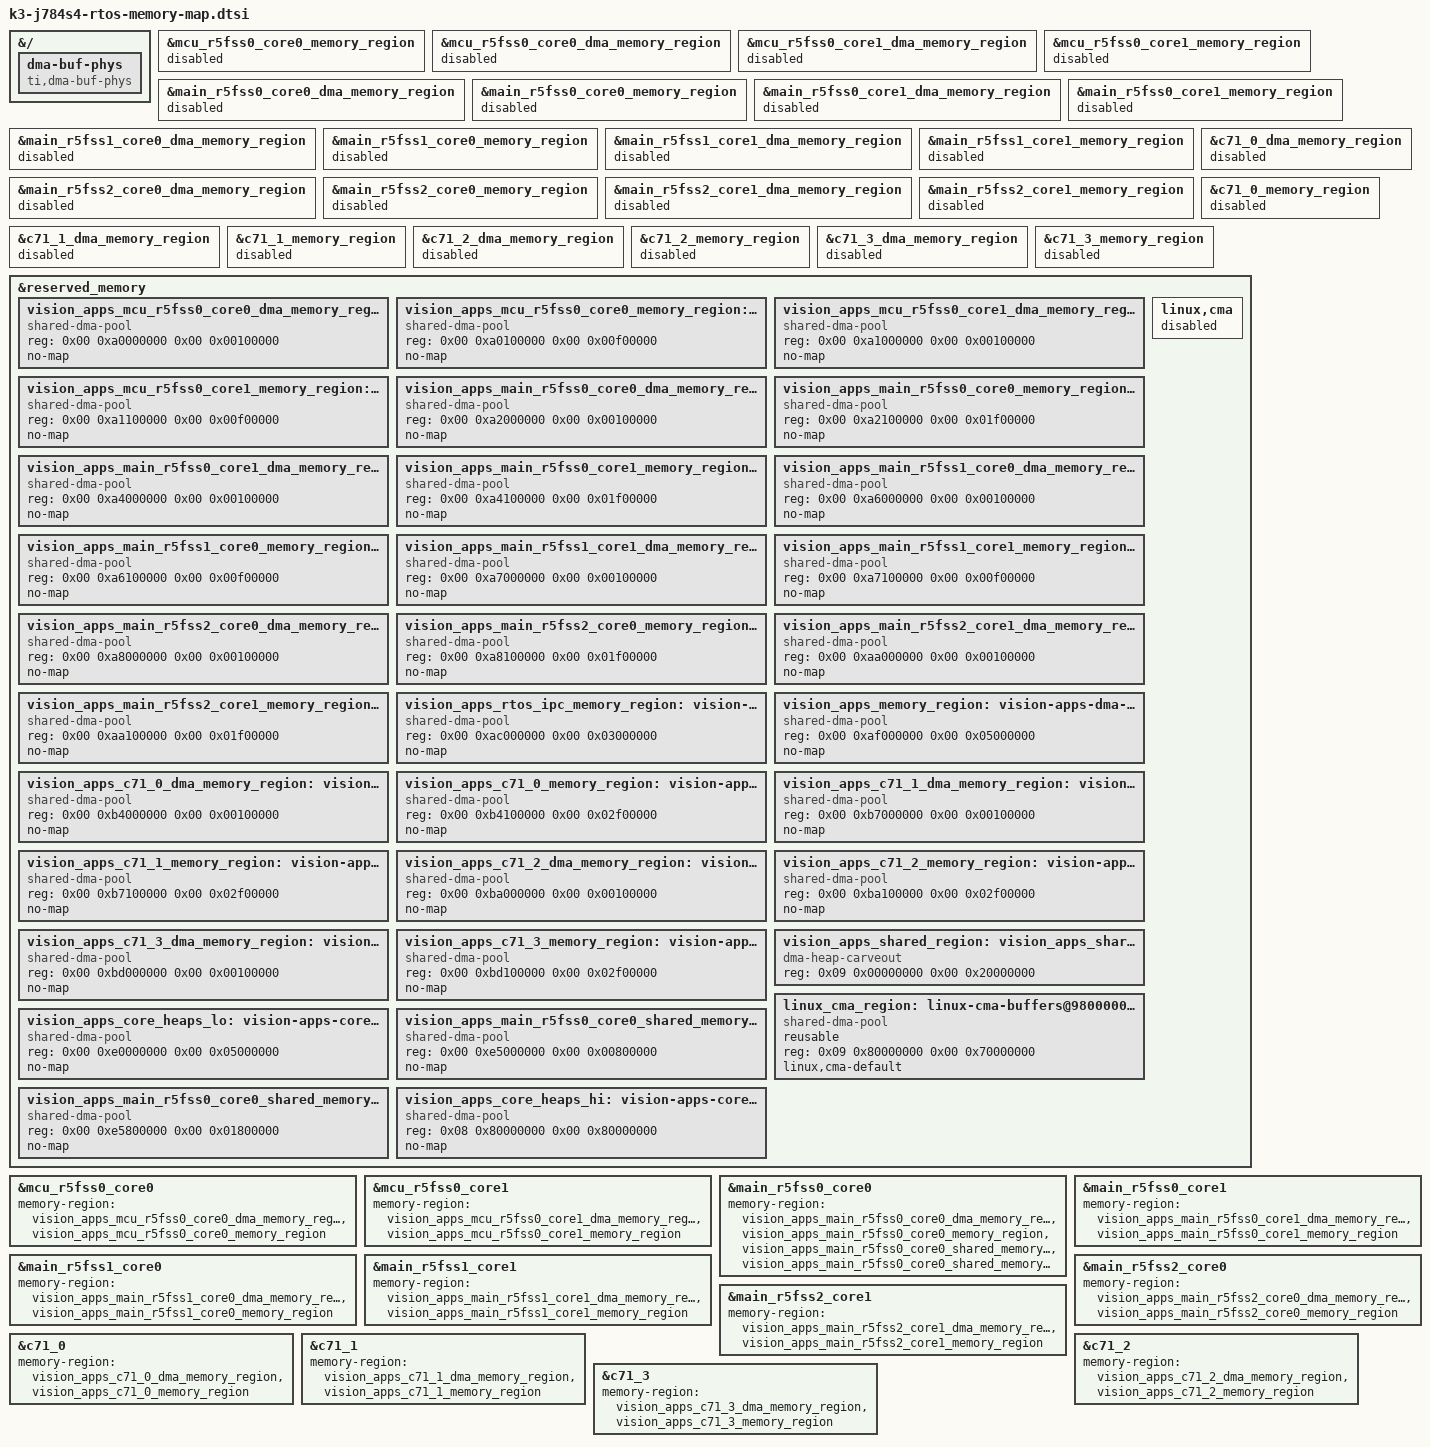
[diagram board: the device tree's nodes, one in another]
// SPDX-License-Identifier: GPL-2.0
/*
 * Vision-apps: device-tree overlay
 *
 * Copyright (C) 2019 - 2022 Texas Instruments Incorporated - http://www.ti.com/
 */

#include <dt-bindings/soc/ti,sci_pm_domain.h>

&{/} {
	dma-buf-phys {
		compatible = "ti,dma-buf-phys";
	};
};

&mcu_r5fss0_core0_memory_region {
	status = "disabled";
};

&mcu_r5fss0_core0_dma_memory_region {
	status = "disabled";
};

&mcu_r5fss0_core1_dma_memory_region {
	status = "disabled";
};

&mcu_r5fss0_core1_memory_region {
	status = "disabled";
};

&main_r5fss0_core0_dma_memory_region {
	status = "disabled";
};

&main_r5fss0_core0_memory_region {
	status = "disabled";
};

&main_r5fss0_core1_dma_memory_region {
	status = "disabled";
};

&main_r5fss0_core1_memory_region {
	status = "disabled";
};

&main_r5fss1_core0_dma_memory_region {
	status = "disabled";
};

&main_r5fss1_core0_memory_region {
	status = "disabled";
};

&main_r5fss1_core1_dma_memory_region {
	status = "disabled";
};

&main_r5fss1_core1_memory_region {
	status = "disabled";
};

&main_r5fss2_core0_dma_memory_region {
	status = "disabled";
};

&main_r5fss2_core0_memory_region {
	status = "disabled";
};

&main_r5fss2_core1_dma_memory_region {
	status = "disabled";
};

&main_r5fss2_core1_memory_region {
	status = "disabled";
};

&c71_0_dma_memory_region {
	status = "disabled";
};

&c71_0_memory_region {
	status = "disabled";
};

&c71_1_dma_memory_region {
	status = "disabled";
};

&c71_1_memory_region {
	status = "disabled";
};

&c71_2_dma_memory_region {
	status = "disabled";
};

&c71_2_memory_region {
	status = "disabled";
};

&c71_3_dma_memory_region {
	status = "disabled";
};

&c71_3_memory_region {
	status = "disabled";
};

&reserved_memory {
	#address-cells = <2>;
	#size-cells = <2>;

	vision_apps_mcu_r5fss0_core0_dma_memory_region: vision-apps-r5f-dma-memory@a0000000 {
		compatible = "shared-dma-pool";
		reg = <0x00 0xa0000000 0x00 0x00100000>;
		no-map;
	};
	vision_apps_mcu_r5fss0_core0_memory_region: vision-apps-r5f-memory@a0100000 {
		compatible = "shared-dma-pool";
		reg = <0x00 0xa0100000 0x00 0x00f00000>;
		no-map;
	};
	vision_apps_mcu_r5fss0_core1_dma_memory_region: vision-apps-r5f-dma-memory@a1000000 {
		compatible = "shared-dma-pool";
		reg = <0x00 0xa1000000 0x00 0x00100000>;
		no-map;
	};
	vision_apps_mcu_r5fss0_core1_memory_region: vision-apps-r5f-memory@a1100000 {
		compatible = "shared-dma-pool";
		reg = <0x00 0xa1100000 0x00 0x00f00000>;
		no-map;
	};
	vision_apps_main_r5fss0_core0_dma_memory_region: vision-apps-r5f-dma-memory@a2000000 {
		compatible = "shared-dma-pool";
		reg = <0x00 0xa2000000 0x00 0x00100000>;
		no-map;
	};
	vision_apps_main_r5fss0_core0_memory_region: vision-apps-r5f-memory@a2100000 {
		compatible = "shared-dma-pool";
		reg = <0x00 0xa2100000 0x00 0x01f00000>;
		no-map;
	};
	vision_apps_main_r5fss0_core1_dma_memory_region: vision-apps-r5f-dma-memory@a4000000 {
		compatible = "shared-dma-pool";
		reg = <0x00 0xa4000000 0x00 0x00100000>;
		no-map;
	};
	vision_apps_main_r5fss0_core1_memory_region: vision-apps-r5f-memory@a4100000 {
		compatible = "shared-dma-pool";
		reg = <0x00 0xa4100000 0x00 0x01f00000>;
		no-map;
	};
	vision_apps_main_r5fss1_core0_dma_memory_region: vision-apps-r5f-dma-memory@a6000000 {
		compatible = "shared-dma-pool";
		reg = <0x00 0xa6000000 0x00 0x00100000>;
		no-map;
	};
	vision_apps_main_r5fss1_core0_memory_region: vision-apps-r5f-memory@a6100000 {
		compatible = "shared-dma-pool";
		reg = <0x00 0xa6100000 0x00 0x00f00000>;
		no-map;
	};
	vision_apps_main_r5fss1_core1_dma_memory_region: vision-apps-r5f-dma-memory@a7000000 {
		compatible = "shared-dma-pool";
		reg = <0x00 0xa7000000 0x00 0x00100000>;
		no-map;
	};
	vision_apps_main_r5fss1_core1_memory_region: vision-apps-r5f-memory@a7100000 {
		compatible = "shared-dma-pool";
		reg = <0x00 0xa7100000 0x00 0x00f00000>;
		no-map;
	};
	vision_apps_main_r5fss2_core0_dma_memory_region: vision-apps-r5f-dma-memory@a8000000 {
		compatible = "shared-dma-pool";
		reg = <0x00 0xa8000000 0x00 0x00100000>;
		no-map;
	};
	vision_apps_main_r5fss2_core0_memory_region: vision-apps-r5f-memory@a8100000 {
		compatible = "shared-dma-pool";
		reg = <0x00 0xa8100000 0x00 0x01f00000>;
		no-map;
	};
	vision_apps_main_r5fss2_core1_dma_memory_region: vision-apps-r5f-dma-memory@aa000000 {
		compatible = "shared-dma-pool";
		reg = <0x00 0xaa000000 0x00 0x00100000>;
		no-map;
	};
	vision_apps_main_r5fss2_core1_memory_region: vision-apps-r5f-memory@aa100000 {
		compatible = "shared-dma-pool";
		reg = <0x00 0xaa100000 0x00 0x01f00000>;
		no-map;
	};
	vision_apps_rtos_ipc_memory_region: vision-apps-rtos-ipc-memory-region@ac000000 {
		compatible = "shared-dma-pool";
		reg = <0x00 0xac000000 0x00 0x03000000>;
		no-map;
	};
	vision_apps_memory_region: vision-apps-dma-memory@af000000 {
		compatible = "shared-dma-pool";
		reg = <0x00 0xaf000000 0x00 0x05000000>;
		no-map;
	};
	vision_apps_c71_0_dma_memory_region: vision-apps-c71-dma-memory@b4000000 {
		compatible = "shared-dma-pool";
		reg = <0x00 0xb4000000 0x00 0x00100000>;
		no-map;
	};
	vision_apps_c71_0_memory_region: vision-apps-c71_0-memory@b4100000 {
		compatible = "shared-dma-pool";
		reg = <0x00 0xb4100000 0x00 0x02f00000>;
		no-map;
	};
	vision_apps_c71_1_dma_memory_region: vision-apps-c71_1-dma-memory@b7000000 {
		compatible = "shared-dma-pool";
		reg = <0x00 0xb7000000 0x00 0x00100000>;
		no-map;
	};
	vision_apps_c71_1_memory_region: vision-apps-c71_1-memory@b7100000 {
		compatible = "shared-dma-pool";
		reg = <0x00 0xb7100000 0x00 0x02f00000>;
		no-map;
	};
	vision_apps_c71_2_dma_memory_region: vision-apps-c71_2-dma-memory@ba000000 {
		compatible = "shared-dma-pool";
		reg = <0x00 0xba000000 0x00 0x00100000>;
		no-map;
	};
	vision_apps_c71_2_memory_region: vision-apps-c71_2-memory@ba100000 {
		compatible = "shared-dma-pool";
		reg = <0x00 0xba100000 0x00 0x02f00000>;
		no-map;
	};
	vision_apps_c71_3_dma_memory_region: vision-apps-c71_3-dma-memory@bd000000 {
		compatible = "shared-dma-pool";
		reg = <0x00 0xbd000000 0x00 0x00100000>;
		no-map;
	};
	vision_apps_c71_3_memory_region: vision-apps-c71_3-memory@bd100000 {
		compatible = "shared-dma-pool";
		reg = <0x00 0xbd100000 0x00 0x02f00000>;
		no-map;
	};
	vision_apps_shared_region: vision_apps_shared-memories {
		compatible = "dma-heap-carveout";
		reg = <0x09 0x00000000 0x00 0x20000000>;
	};
	linux,cma {
		status = "disabled";
	};
	linux_cma_region: linux-cma-buffers@980000000 {
		compatible = "shared-dma-pool";
		reusable;
		reg = <0x09 0x80000000 0x00 0x70000000>;
		linux,cma-default;
	};
	vision_apps_core_heaps_lo: vision-apps-core-heap-memory-lo@e0000000 {
		compatible = "shared-dma-pool";
		reg = <0x00 0xe0000000 0x00 0x05000000>;
		no-map;
	};
	vision_apps_main_r5fss0_core0_shared_memory_queue_region: vision-apps-r5f-virtual-eth-queues@e5000000 {
		compatible = "shared-dma-pool";
		reg = <0x00 0xe5000000 0x00 0x00800000>;
		no-map;
	};
	vision_apps_main_r5fss0_core0_shared_memory_bufpool_region: vision-apps-r5f-virtual-eth-buffers@e5800000 {
		compatible = "shared-dma-pool";
		reg = <0x00 0xe5800000 0x00 0x01800000>;
		no-map;
	};
	vision_apps_core_heaps_hi: vision-apps-core-heap-memory-hi@880000000 {
		compatible = "shared-dma-pool";
		reg = <0x08 0x80000000 0x00 0x80000000>;
		no-map;
	};
};

&mcu_r5fss0_core0 {
	memory-region = <&vision_apps_mcu_r5fss0_core0_dma_memory_region>,
			<&vision_apps_mcu_r5fss0_core0_memory_region>;
};

&mcu_r5fss0_core1 {
	memory-region = <&vision_apps_mcu_r5fss0_core1_dma_memory_region>,
			<&vision_apps_mcu_r5fss0_core1_memory_region>;
};

&main_r5fss0_core0 {
	memory-region = <&vision_apps_main_r5fss0_core0_dma_memory_region>,
			<&vision_apps_main_r5fss0_core0_memory_region>,
			<&vision_apps_main_r5fss0_core0_shared_memory_queue_region>,
			<&vision_apps_main_r5fss0_core0_shared_memory_bufpool_region>;
};

&main_r5fss0_core1 {
	memory-region = <&vision_apps_main_r5fss0_core1_dma_memory_region>,
			<&vision_apps_main_r5fss0_core1_memory_region>;
};

&main_r5fss1_core0 {
	memory-region = <&vision_apps_main_r5fss1_core0_dma_memory_region>,
			<&vision_apps_main_r5fss1_core0_memory_region>;
};

&main_r5fss1_core1 {
	memory-region = <&vision_apps_main_r5fss1_core1_dma_memory_region>,
			<&vision_apps_main_r5fss1_core1_memory_region>;
};

&main_r5fss2_core0 {
	memory-region = <&vision_apps_main_r5fss2_core0_dma_memory_region>,
			<&vision_apps_main_r5fss2_core0_memory_region>;
};

&main_r5fss2_core1 {
	memory-region = <&vision_apps_main_r5fss2_core1_dma_memory_region>,
			<&vision_apps_main_r5fss2_core1_memory_region>;
};

&c71_0 {
	memory-region = <&vision_apps_c71_0_dma_memory_region>,
			<&vision_apps_c71_0_memory_region>;
};

&c71_1 {
	memory-region = <&vision_apps_c71_1_dma_memory_region>,
			<&vision_apps_c71_1_memory_region>;
};

&c71_2 {
	memory-region = <&vision_apps_c71_2_dma_memory_region>,
			<&vision_apps_c71_2_memory_region>;
};

&c71_3 {
	memory-region = <&vision_apps_c71_3_dma_memory_region>,
			<&vision_apps_c71_3_memory_region>;
};
